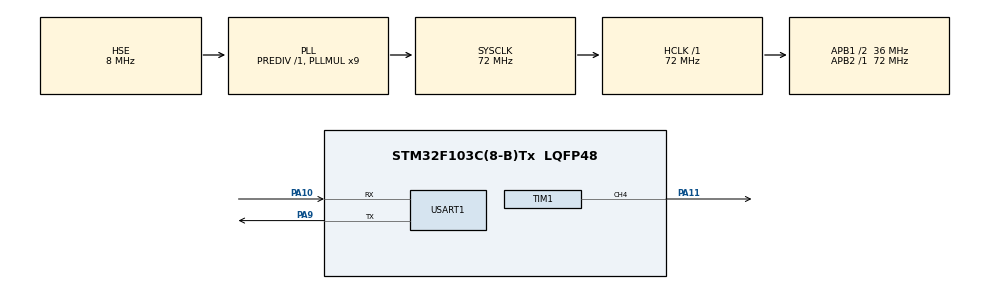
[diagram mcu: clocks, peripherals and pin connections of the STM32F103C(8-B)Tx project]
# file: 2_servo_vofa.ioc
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Mcu.Family=STM32F1
Mcu.Name=STM32F103C(8-B)Tx
Mcu.Package=LQFP48
NVIC.PriorityGroup=NVIC_PRIORITYGROUP_4
NVIC.USART1_IRQn=true\:0\:0\:false\:false\:true\:true\:true\:true
PA10.Mode=Asynchronous
PA10.Signal=USART1_RX
PA11.Signal=S_TIM1_CH4
PA13.Mode=Serial_Wire
PA13.Signal=SYS_JTMS-SWDIO
PA14.Mode=Serial_Wire
PA14.Signal=SYS_JTCK-SWCLK
PA9.Mode=Asynchronous
PA9.Signal=USART1_TX
PD0-OSC_IN.Mode=HSE-External-Oscillator
PD0-OSC_IN.Signal=RCC_OSC_IN
PD1-OSC_OUT.Mode=HSE-External-Oscillator
PD1-OSC_OUT.Signal=RCC_OSC_OUT
ProjectManager.HeapSize=0x200
ProjectManager.StackSize=0x400
ProjectManager.TargetToolchain=CMake
RCC.AHBFreq_Value=72000000
RCC.APB1CLKDivider=RCC_HCLK_DIV2
RCC.APB1Freq_Value=36000000
RCC.APB1TimFreq_Value=72000000
RCC.APB2Freq_Value=72000000
RCC.APB2TimFreq_Value=72000000
RCC.HCLKFreq_Value=72000000
RCC.PLLMUL=RCC_PLL_MUL9
RCC.PLLSourceVirtual=RCC_PLLSOURCE_HSE
RCC.SYSCLKFreq_VALUE=72000000
RCC.SYSCLKSource=RCC_SYSCLKSOURCE_PLLCLK
RCC.USBFreq_Value=72000000
SH.S_TIM1_CH4.0=TIM1_CH4,PWM Generation4 CH4
TIM1.Channel-PWM\ Generation4\ CH4=TIM_CHANNEL_4
TIM1.Period=20000-1
TIM1.Prescaler=72-1
USART1.VirtualMode=VM_ASYNC
board=custom

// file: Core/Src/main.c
/* USER CODE BEGIN Header */
/**
  ******************************************************************************
  * @file           : main.c
  * @brief          : Main program body
  ******************************************************************************
  * @attention
  *
  * Copyright (c) 2026 STMicroelectronics.
  * All rights reserved.
  *
  * This software is licensed under terms that can be found in the LICENSE file
  * in the root directory of this software component.
  * If no LICENSE file comes with this software, it is provided AS-IS.
  *
  ******************************************************************************
  */
/* USER CODE END Header */
#include "main.h"
#include "tim.h"
#include "usart.h"
#include "gpio.h"

/* USER CODE BEGIN PD */
#define SERVO_MIN_ANGLE_DEG      0.0f
#define SERVO_MAX_ANGLE_DEG      180.0f
#define SERVO_MIN_PULSE_US       500.0f
#define SERVO_MAX_PULSE_US       2500.0f
#define SERVO_PWM_PERIOD_US      20000.0f
#define VOFA_CHANNEL_COUNT       2U
#define UART_COMMAND_BUFFER_SIZE 16U

/* USER CODE END PD */

/* USER CODE BEGIN PV */
static float current_angle = 90.0f;
static uint8_t uart_rx_byte = 0U;
static char uart_command_buffer[UART_COMMAND_BUFFER_SIZE] = {0};
static uint8_t uart_command_index = 0U;

/* USER CODE END PV */

void SystemClock_Config(void);
/* USER CODE BEGIN PFP */
static float Servo_LimitAngle(float angle);
static uint16_t Servo_AngleToPulse(float angle);
static void Servo_SetAngle(float angle);
static float Servo_GetDuty(float angle);
static void VOFA_SendFloat(float angle, float duty);
static void UART_CommandProcessByte(uint8_t byte);
static void UART_CommandProcessLine(const char *line);
static uint8_t UART_CommandParseAngle(const char *line, float *angle);

/* USER CODE END PFP */

int main(void)
{

  /* MCU Configuration--------------------------------------------------------*/

  /* Reset of all peripherals, Initializes the Flash interface and the Systick. */
  HAL_Init();

  /* Configure the system clock */
  SystemClock_Config();

  /* Initialize all configured peripherals */
  MX_GPIO_Init();
  MX_TIM1_Init();
  MX_USART1_UART_Init();
  /* USER CODE BEGIN 2 */
  HAL_TIM_PWM_Start(&htim1, TIM_CHANNEL_4);
  Servo_SetAngle(current_angle);
  HAL_UART_Receive_IT(&huart1, &uart_rx_byte, 1);

  /* USER CODE END 2 */

  /* Infinite loop */
  while (1)
  {

    /* USER CODE BEGIN 3 */
    VOFA_SendFloat(current_angle, Servo_GetDuty(current_angle));
    HAL_Delay(20);
  }
  /* USER CODE END 3 */
}

void SystemClock_Config(void)
{
  RCC_OscInitTypeDef RCC_OscInitStruct = {0};
  RCC_ClkInitTypeDef RCC_ClkInitStruct = {0};

  /** Initializes the RCC Oscillators according to the specified parameters
  * in the RCC_OscInitTypeDef structure.
  */
  RCC_OscInitStruct.OscillatorType = RCC_OSCILLATORTYPE_HSE;
  RCC_OscInitStruct.HSEState = RCC_HSE_ON;
  RCC_OscInitStruct.HSEPredivValue = RCC_HSE_PREDIV_DIV1;
  RCC_OscInitStruct.HSIState = RCC_HSI_ON;
  RCC_OscInitStruct.PLL.PLLState = RCC_PLL_ON;
  RCC_OscInitStruct.PLL.PLLSource = RCC_PLLSOURCE_HSE;
  RCC_OscInitStruct.PLL.PLLMUL = RCC_PLL_MUL9;
  if (HAL_RCC_OscConfig(&RCC_OscInitStruct) != HAL_OK)
  {
    Error_Handler();
  }

  /** Initializes the CPU, AHB and APB buses clocks
  */
  RCC_ClkInitStruct.ClockType = RCC_CLOCKTYPE_HCLK|RCC_CLOCKTYPE_SYSCLK
                              |RCC_CLOCKTYPE_PCLK1|RCC_CLOCKTYPE_PCLK2;
  RCC_ClkInitStruct.SYSCLKSource = RCC_SYSCLKSOURCE_PLLCLK;
  RCC_ClkInitStruct.AHBCLKDivider = RCC_SYSCLK_DIV1;
  RCC_ClkInitStruct.APB1CLKDivider = RCC_HCLK_DIV2;
  RCC_ClkInitStruct.APB2CLKDivider = RCC_HCLK_DIV1;

  if (HAL_RCC_ClockConfig(&RCC_ClkInitStruct, FLASH_LATENCY_2) != HAL_OK)
  {
    Error_Handler();
  }
}

/* USER CODE BEGIN 4 */
static float Servo_LimitAngle(float angle)
{
  if (angle < SERVO_MIN_ANGLE_DEG)
  {
    return SERVO_MIN_ANGLE_DEG;
  }
  if (angle > SERVO_MAX_ANGLE_DEG)
  {
    return SERVO_MAX_ANGLE_DEG;
  }
  return angle;
}

static uint16_t Servo_AngleToPulse(float angle)
{
  const float limited_angle = Servo_LimitAngle(angle);
  const float pulse_range = SERVO_MAX_PULSE_US - SERVO_MIN_PULSE_US;
  const float angle_range = SERVO_MAX_ANGLE_DEG - SERVO_MIN_ANGLE_DEG;
  const float pulse = SERVO_MIN_PULSE_US + limited_angle * pulse_range / angle_range;

  return (uint16_t)(pulse + 0.5f);
}

static void Servo_SetAngle(float angle)
{
  current_angle = Servo_LimitAngle(angle);
  __HAL_TIM_SET_COMPARE(&htim1, TIM_CHANNEL_4, Servo_AngleToPulse(current_angle));
}

static float Servo_GetDuty(float angle)
{
  return (float)Servo_AngleToPulse(angle) * 100.0f / SERVO_PWM_PERIOD_US;
}

static void VOFA_SendFloat(float angle, float duty)
{
  float data[VOFA_CHANNEL_COUNT] = {angle, duty};
  uint8_t tail[4] = {0x00, 0x00, 0x80, 0x7F};

  HAL_UART_Transmit(&huart1, (uint8_t *)data, sizeof(data), 100);
  HAL_UART_Transmit(&huart1, tail, sizeof(tail), 100);
}

static void UART_CommandProcessByte(uint8_t byte)
{
  if (byte == '\r')
  {
    return;
  }

  if (byte == '\n')
  {
    uart_command_buffer[uart_command_index] = '\0';
    UART_CommandProcessLine(uart_command_buffer);
    uart_command_index = 0U;
    return;
  }

  if (uart_command_index < (UART_COMMAND_BUFFER_SIZE - 1U))
  {
    uart_command_buffer[uart_command_index] = (char)byte;
    uart_command_index++;
  }
  else
  {
    uart_command_index = 0U;
  }
}

static void UART_CommandProcessLine(const char *line)
{
  float angle = 0.0f;

  if (UART_CommandParseAngle(line, &angle) != 0U)
  {
    Servo_SetAngle(angle);
  }
}

static uint8_t UART_CommandParseAngle(const char *line, float *angle)
{
  float value = 0.0f;
  float decimal = 0.1f;
  uint8_t has_digit = 0U;

  while ((*line != '\0') && ((*line < '0') || (*line > '9')) && (*line != '.'))
  {
    line++;
  }

  while ((*line >= '0') && (*line <= '9'))
  {
    value = value * 10.0f + (float)(*line - '0');
    has_digit = 1U;
    line++;
  }

  if (*line == '.')
  {
    line++;
    while ((*line >= '0') && (*line <= '9'))
    {
      value += (float)(*line - '0') * decimal;
      decimal *= 0.1f;
      has_digit = 1U;
      line++;
    }
  }

  if (has_digit == 0U)
  {
    return 0U;
  }

  *angle = value;
  return 1U;
}

void HAL_UART_RxCpltCallback(UART_HandleTypeDef *huart)
{
  if (huart->Instance == USART1)
  {
    UART_CommandProcessByte(uart_rx_byte);
    HAL_UART_Receive_IT(&huart1, &uart_rx_byte, 1);
  }
}

/* USER CODE END 4 */

void Error_Handler(void)
{
  __disable_irq();
  while (1)
  {
  }
}
